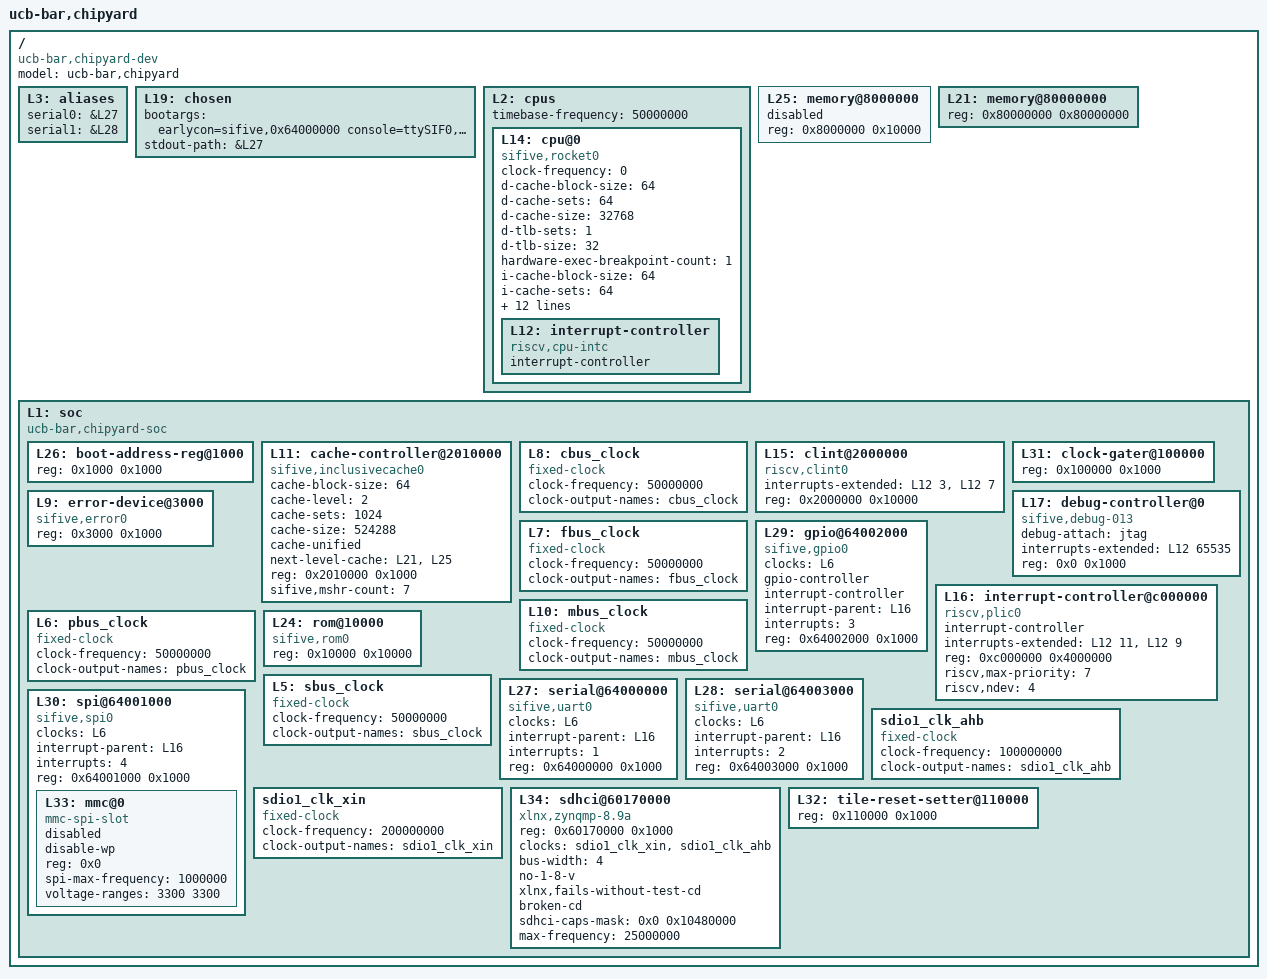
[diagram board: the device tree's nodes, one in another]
/dts-v1/;

/ {
	#address-cells = <1>;
	#size-cells = <1>;
	compatible = "ucb-bar,chipyard-dev";
	model = "ucb-bar,chipyard";
	L3: aliases {
		serial0 = &L27;
		serial1 = &L28;
	};
	L19: chosen {
			bootargs = "earlycon=sifive,0x64000000 console=ttySIF0,115200n8 init=/init loglevel=8 ignore_loglevel";
		stdout-path = &L27;
	};
	L2: cpus {
		#address-cells = <1>;
		#size-cells = <0>;
		timebase-frequency = <50000000>;
		L14: cpu@0 {
			clock-frequency = <0>;
			compatible = "sifive,rocket0", "riscv";
			d-cache-block-size = <64>;
			d-cache-sets = <64>;
			d-cache-size = <32768>;
			d-tlb-sets = <1>;
			d-tlb-size = <32>;
			device_type = "cpu";
			hardware-exec-breakpoint-count = <1>;
			i-cache-block-size = <64>;
			i-cache-sets = <64>;
			i-cache-size = <32768>;
			i-tlb-sets = <1>;
			i-tlb-size = <32>;
			mmu-type = "riscv,sv39";
			next-level-cache = <&L11>;
			reg = <0x0>;
			riscv,isa = "rv64imafdczicsr_zifencei_zihpm_zfh_xrocket";
			riscv,pmpgranularity = <4>;
			riscv,pmpregions = <8>;
			status = "okay";
			timebase-frequency = <50000000>;
			tlb-split;
			L12: interrupt-controller {
				#interrupt-cells = <1>;
				compatible = "riscv,cpu-intc";
				interrupt-controller;
			};
		};
	};
	L25: memory@8000000 {
		device_type = "memory";
		reg = <0x8000000 0x10000>;
		status = "disabled";
	};
	L21: memory@80000000 {
		device_type = "memory";
		reg = <0x80000000 0x80000000>;
	};
	L1: soc {
		#address-cells = <1>;
		#size-cells = <1>;
		compatible = "ucb-bar,chipyard-soc", "simple-bus";
		ranges;
		L26: boot-address-reg@1000 {
			reg = <0x1000 0x1000>;
			reg-names = "control";
		};
		L11: cache-controller@2010000 {
			cache-block-size = <64>;
			cache-level = <2>;
			cache-sets = <1024>;
			cache-size = <524288>;
			cache-unified;
			compatible = "sifive,inclusivecache0", "cache";
			next-level-cache = <&L21 &L25>;
			reg = <0x2010000 0x1000>;
			reg-names = "control";
			sifive,mshr-count = <7>;
		};
		L8: cbus_clock {
			#clock-cells = <0>;
			clock-frequency = <50000000>;
			clock-output-names = "cbus_clock";
			compatible = "fixed-clock";
		};
		L15: clint@2000000 {
			compatible = "riscv,clint0";
			interrupts-extended = <&L12 3 &L12 7>;
			reg = <0x2000000 0x10000>;
			reg-names = "control";
		};
		L31: clock-gater@100000 {
			reg = <0x100000 0x1000>;
			reg-names = "control";
		};
		L17: debug-controller@0 {
			compatible = "sifive,debug-013", "riscv,debug-013";
			debug-attach = "jtag";
			interrupts-extended = <&L12 65535>;
			reg = <0x0 0x1000>;
			reg-names = "control";
		};
		L9: error-device@3000 {
			compatible = "sifive,error0";
			reg = <0x3000 0x1000>;
		};
		L7: fbus_clock {
			#clock-cells = <0>;
			clock-frequency = <50000000>;
			clock-output-names = "fbus_clock";
			compatible = "fixed-clock";
		};
		L29: gpio@64002000 {
			#gpio-cells = <2>;
			#interrupt-cells = <2>;
			clocks = <&L6>;
			compatible = "sifive,gpio0", "sifive,gpio1";
			gpio-controller;
			interrupt-controller;
			interrupt-parent = <&L16>;
			interrupts = <3>;
			reg = <0x64002000 0x1000>;
			reg-names = "control";
		};
		L16: interrupt-controller@c000000 {
			#interrupt-cells = <1>;
			compatible = "riscv,plic0";
			interrupt-controller;
			interrupts-extended = <&L12 11 &L12 9>;
			reg = <0xc000000 0x4000000>;
			reg-names = "control";
			riscv,max-priority = <7>;
			riscv,ndev = <4>;
		};
		L10: mbus_clock {
			#clock-cells = <0>;
			clock-frequency = <50000000>;
			clock-output-names = "mbus_clock";
			compatible = "fixed-clock";
		};
		L6: pbus_clock {
			#clock-cells = <0>;
			clock-frequency = <50000000>;
			clock-output-names = "pbus_clock";
			compatible = "fixed-clock";
		};
		L24: rom@10000 {
			compatible = "sifive,rom0";
			reg = <0x10000 0x10000>;
			reg-names = "mem";
		};
		L5: sbus_clock {
			#clock-cells = <0>;
			clock-frequency = <50000000>;
			clock-output-names = "sbus_clock";
			compatible = "fixed-clock";
		};
		L27: serial@64000000 {
			clocks = <&L6>;
			compatible = "sifive,uart0";
			interrupt-parent = <&L16>;
			interrupts = <1>;
			reg = <0x64000000 0x1000>;
			reg-names = "control";
		};
		L28: serial@64003000 {
			clocks = <&L6>;
			compatible = "sifive,uart0";
			interrupt-parent = <&L16>;
			interrupts = <2>;
			reg = <0x64003000 0x1000>;
			reg-names = "control";
		};
		L30: spi@64001000 {
			#address-cells = <1>;
			#size-cells = <0>;
			clocks = <&L6>;
			compatible = "sifive,spi0";
			interrupt-parent = <&L16>;
			interrupts = <4>;
			reg = <0x64001000 0x1000>;
			reg-names = "control";
			L33: mmc@0 {
				compatible = "mmc-spi-slot";
				disable-wp;
				reg = <0x0>;
				spi-max-frequency = <1000000>;
				voltage-ranges = <3300 3300>;
				/* J100-ONLY: SPI-SD path disabled; active SD path is sdhci@60170000 (J100) */
				status = "disabled";
			};
		};
		/*
		 * PS SDIO1 via A2 PSLPD path (Rocket 0x60170000 → PS 0xFF170000).
		 * J100 full-size SD slot on ZCU104 board.
		 *
		 * Clocks: PS hardware supplies the actual clocks internally;
		 * these fixed-clock nodes satisfy the arasan driver's
		 * devm_clk_get("clk_ahb") / devm_clk_get("clk_xin") calls.
		 *   clk_ahb  = LPD_LSBUS_CLK  ≈ 100 MHz
		 *   clk_xin  = SDIO1_REF_CLK  ≈ 200 MHz (psu_init sets this)
		 *
		 * Interrupts: PLIC has only 4 HW sources (ndev=4); PS SDIO1 IRQ
		 * goes to PS GIC only (not routed to PLIC). No interrupt-parent
		 * or interrupts property here — platform_get_irq_optional()
		 * returns -ENXIO, and the patched sdhci driver falls back to
		 * a 10ms poll timer for I/O completion.
		 * NOTE: Do NOT add interrupt-parent/interrupts with an IRQ
		 * beyond ndev — PLIC irq_domain mapping will hang on MMIO
		 * access to non-existent registers.
		 */
		sdio1_clk_ahb: sdio1_clk_ahb {
			#clock-cells = <0>;
			clock-frequency = <100000000>;
			clock-output-names = "sdio1_clk_ahb";
			compatible = "fixed-clock";
		};
		sdio1_clk_xin: sdio1_clk_xin {
			#clock-cells = <0>;
			clock-frequency = <200000000>;
			clock-output-names = "sdio1_clk_xin";
			compatible = "fixed-clock";
		};
		L34: sdhci@60170000 {
			compatible = "xlnx,zynqmp-8.9a", "arasan,sdhci-8.9a";
			reg = <0x60170000 0x1000>;
			clocks = <&sdio1_clk_xin>, <&sdio1_clk_ahb>;
			clock-names = "clk_xin", "clk_ahb";
			bus-width = <4>;
			no-1-8-v;
			xlnx,fails-without-test-cd;
			broken-cd;
			/* Disable ADMA2 (bit19), SDMA (bit22), and 64-bit addr (bit28).
			 * Root cause: Rocket DDR is at PA 0x80000000+ but PS SDIO1 DMA engine
			 * uses PS-side DDR addresses (0x00000000+). ADMA/SDMA descriptors
			 * contain Rocket PAs which map to wrong PS-side location → DMA stalls.
			 * PIO mode: CPU reads card data directly from SDHCI FIFO via AXI bridge
			 * at 0x60170020 → avoids all DMA address translation issues.
			 * DT u64 encoding: <high32 low32> → lower_32_bits = low32 = caps mask.
			 * MUST be <0x0 0x10480000>: low32=0x10480000 masks CAPS bits 19/22/28.
			 * Wrong: <0x10480000 0x0> → low32=0x0 → no bits cleared → ADMA enabled! */
			sdhci-caps-mask = <0x0 0x10480000>;
			/* Raise clock to 25MHz for SD data transfers via PS SDIO1 AXI bridge. */
			max-frequency = <25000000>;
			/* J100-ONLY: active SD path — PS SDIO1 via saxigp6 (Rocket 0x60170000 -> PS 0xFF170000) */
			status = "okay";
		};
		L32: tile-reset-setter@110000 {
			reg = <0x110000 0x1000>;
			reg-names = "control";
		};
	};
};
